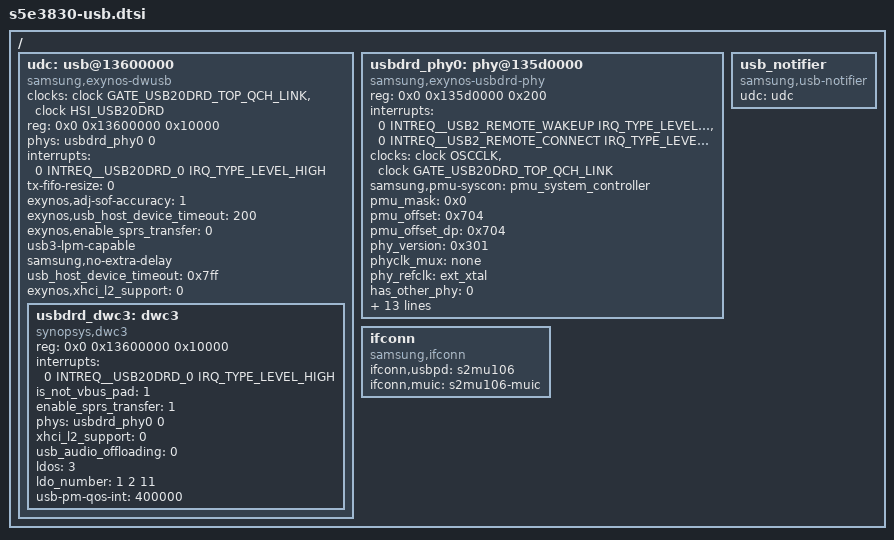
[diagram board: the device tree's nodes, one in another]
/*
 * Samsung's Exynos SoC USB device tree source
 *
 * Copyright (c) 2020 Samsung Electronics Co., Ltd.
 *		http://www.samsung.com
 *
 * Samsung's Exynos2100 SoC USB channels are listed as device
 * tree nodes are listed in this file.
 *
 * This program is free software; you can redistribute it and/or modify
 * it under the terms of the GNU General Public License version 2 as
 * published by the Free Software Foundation.
 */

#include <dt-bindings/interrupt-controller/arm-gic.h>
#include <dt-bindings/interrupt-controller/s5e3830.h>

/ {
	udc: usb@13600000 {
		compatible = "samsung,exynos-dwusb";
		clocks = <&clock GATE_USB20DRD_TOP_QCH_LINK>, <&clock HSI_USB20DRD>;
		clock-names = "aclk", "sclk";
		reg = <0x0 0x13600000 0x10000>;
		#address-cells = <2>;
		#size-cells = <1>;
		ranges;
		//power-domains = <&pd_hsi>;
		status = "okay";
		phys = <&usbdrd_phy0 0>;
		phy-names = "usb2-phy";
		interrupts = <0 INTREQ__USB20DRD_0 IRQ_TYPE_LEVEL_HIGH>;
		tx-fifo-resize = <0>;
		exynos,adj-sof-accuracy = <1>;
		exynos,usb_host_device_timeout = <200>;
		exynos,enable_sprs_transfer = <0>;

		usb3-lpm-capable;
		samsung,no-extra-delay;
		usb_host_device_timeout = <0x7ff>; /* Max value */

		exynos,xhci_l2_support = <0>;

		usbdrd_dwc3: dwc3 {
			compatible = "synopsys,dwc3";
			reg = <0x0 0x13600000 0x10000>;
			interrupts = <0 INTREQ__USB20DRD_0 IRQ_TYPE_LEVEL_HIGH>;
			is_not_vbus_pad = <1>;
			enable_sprs_transfer = <1>;
			phys = <&usbdrd_phy0 0>;
			phy-names = "usb2-phy";
			/* check susphy support */
			xhci_l2_support = <0>;
			/* support usb audio offloading: 1, if not: 0 */
			usb_audio_offloading = <0>;
			//abox = <&abox>; /* Temporary block */
			/* support USB L2 sleep */
			ldos = <3>;
			ldo_number = <1 2 11>;
			/* INT min lock support */
			usb-pm-qos-int = <400000>;
			status = "okay";
		};
	};

	usbdrd_phy0: phy@135d0000 {
		compatible = "samsung,exynos-usbdrd-phy";
		reg = <0x0 0x135d0000 0x200>;
		interrupts = <0 INTREQ__USB2_REMOTE_WAKEUP IRQ_TYPE_LEVEL_HIGH>,
			     <0 INTREQ__USB2_REMOTE_CONNECT IRQ_TYPE_LEVEL_HIGH>;
		clocks = <&clock OSCCLK>, <&clock GATE_USB20DRD_TOP_QCH_LINK>;
		clock-names = "ext_xtal", "aclk";
		samsung,pmu-syscon = <&pmu_system_controller>;
		pmu_mask = <0x0>;
		pmu_offset = <0x704>;
		pmu_offset_dp = <0x704>;

		/* USBDP combo phy version  - 0x200 */
		phy_version = <0x301>;
		/* if it doesn't need phy user mux, */
		/*  you should write "none" */
		/*  but refclk shouldn't be omitted */
		phyclk_mux = "none";
		phy_refclk = "ext_xtal";

		/* if Main phy has the other phy, it must be set to 1. jusf for usbphy_info */
		has_other_phy = <0>;
		/* if combo phy is used, it must be set to 1. usbphy_sub_info is enabled */
		has_combo_phy = <0>;
		sub_phy_version = <0x400>;

		/* ip type */
		/* USB3DRD = 0 */
		/*  USB3HOST = 1 */
		/*  USB2DRD = 2 */
		/*  USB2HOST = 3 */
		ip_type = <0x0>;

		/* for PHY CAL */
		/* choice only one item */
		phy_refsel_clockcore = <1>;
		phy_refsel_ext_osc = <0>;
		phy_refsel_xtal = <0>;
		phy_refsel_diff_pad = <0>;
		phy_refsel_diff_internal = <0>;
		phy_refsel_diff_single = <0>;

		/* true : 1 , false : 0 */
		use_io_for_ovc = <0>;
		common_block_disable = <1>;
		is_not_vbus_pad = <1>;
		used_phy_port = <0>;

		status = "okay";

		#phy-cells = <1>;
		ranges;
       };

	usb_notifier {
		compatible = "samsung,usb-notifier";
		udc = <&udc>;
		status = "okay";
	};

	ifconn {
		status = "okay";
		compatible = "samsung,ifconn";
		ifconn,usbpd = "s2mu106";
		ifconn,muic = "s2mu106-muic";
	};
};
